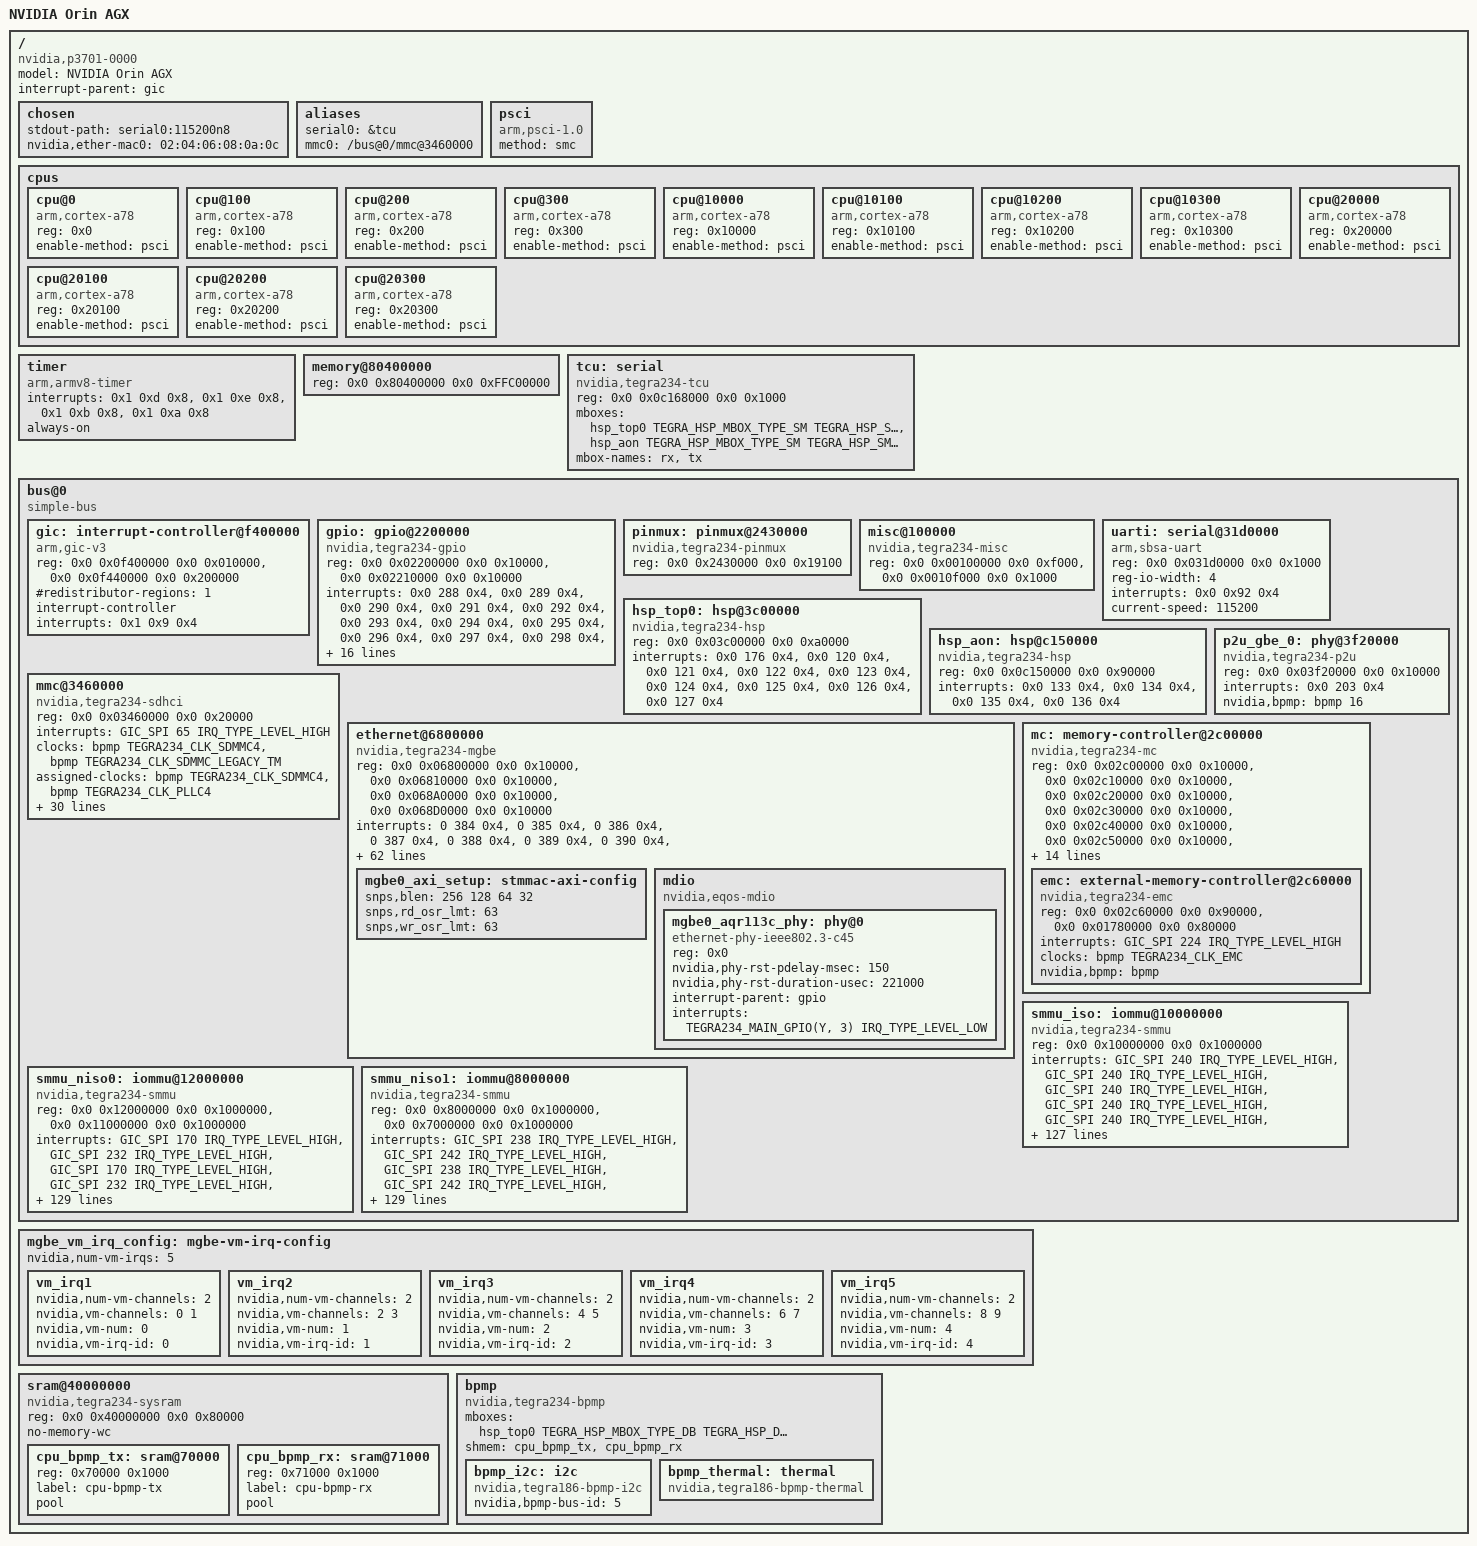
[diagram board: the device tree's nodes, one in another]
/*
 * Copyright 2024, Technology Innovation Institute
 *
 * SPDX-License-Identifier: GPL-2.0-only
 *
 * Device tree for NVIDIA Orin AGX (Tegra234)
 * Minimal DTS for seL4 kernel boot
 */

/dts-v1/;

/* dt-bindings headers for symbolic constants (requires cpp preprocessing) */
#include <dt-bindings/clock/tegra234-clock.h>
#include <dt-bindings/gpio/tegra234-gpio.h>
#include <dt-bindings/interrupt-controller/arm-gic.h>
#include <dt-bindings/mailbox/tegra186-hsp.h>
#include <dt-bindings/memory/tegra234-mc.h>
#include <dt-bindings/power/tegra234-powergate.h>
#include <dt-bindings/reset/tegra234-reset.h>

/ {
	model = "NVIDIA Orin AGX";
	compatible = "nvidia,p3701-0000", "nvidia,tegra234";
	interrupt-parent = <&gic>;
	#address-cells = <0x2>;
	#size-cells = <0x2>;

	chosen {
		stdout-path = "serial0:115200n8";
		/* MAC address for MGBE0 (nvidia,mac-addr-idx=0) */
		nvidia,ether-mac0 = "02:04:06:08:0a:0c";
	};

	aliases {
		serial0 = &tcu;
		mmc0 = "/bus@0/mmc@3460000";
	};

	psci {
		compatible = "arm,psci-1.0", "arm,psci-0.2";
		method = "smc";
	};

	cpus {
		#address-cells = <0x1>;
		#size-cells = <0x0>;

		cpu@0 {
			compatible = "arm,cortex-a78";
			reg = <0x0>;
			device_type = "cpu";
			enable-method = "psci";
		};

		cpu@100 {
			compatible = "arm,cortex-a78";
			reg = <0x100>;
			device_type = "cpu";
			enable-method = "psci";
		};

		cpu@200 {
			compatible = "arm,cortex-a78";
			reg = <0x200>;
			device_type = "cpu";
			enable-method = "psci";
		};

		cpu@300 {
			compatible = "arm,cortex-a78";
			reg = <0x300>;
			device_type = "cpu";
			enable-method = "psci";
		};

		cpu@10000 {
			compatible = "arm,cortex-a78";
			reg = <0x10000>;
			device_type = "cpu";
			enable-method = "psci";
		};

		cpu@10100 {
			compatible = "arm,cortex-a78";
			reg = <0x10100>;
			device_type = "cpu";
			enable-method = "psci";
		};

		cpu@10200 {
			compatible = "arm,cortex-a78";
			reg = <0x10200>;
			device_type = "cpu";
			enable-method = "psci";
		};

		cpu@10300 {
			compatible = "arm,cortex-a78";
			reg = <0x10300>;
			device_type = "cpu";
			enable-method = "psci";
		};

		cpu@20000 {
			compatible = "arm,cortex-a78";
			reg = <0x20000>;
			device_type = "cpu";
			enable-method = "psci";
		};

		cpu@20100 {
			compatible = "arm,cortex-a78";
			reg = <0x20100>;
			device_type = "cpu";
			enable-method = "psci";
		};

		cpu@20200 {
			compatible = "arm,cortex-a78";
			reg = <0x20200>;
			device_type = "cpu";
			enable-method = "psci";
		};

		cpu@20300 {
			compatible = "arm,cortex-a78";
			reg = <0x20300>;
			device_type = "cpu";
			enable-method = "psci";
		};
	};

	timer {
		compatible = "arm,armv8-timer";
		interrupts = <0x1 0xd 0x8>,  /* Secure Phys IRQ */
			     <0x1 0xe 0x8>,  /* Non-secure Phys IRQ */
			     <0x1 0xb 0x8>,  /* Virt IRQ */
			     <0x1 0xa 0x8>;  /* Hyp IRQ */
		always-on;
	};

	memory@80400000 {
		device_type = "memory";
		/* 4092MB RAM starting at 0x80400000 */
		reg = <0x0 0x80400000 0x0 0xFFC00000>;
	};

        tcu: serial {
                compatible = "nvidia,tegra234-tcu", "nvidia,tegra194-tcu";
                reg = <0x0 0x0c168000 0x0 0x1000>;
                mboxes = <&hsp_top0 TEGRA_HSP_MBOX_TYPE_SM TEGRA_HSP_SM_RX(0)>,
                         <&hsp_aon TEGRA_HSP_MBOX_TYPE_SM TEGRA_HSP_SM_TX(1)>;
                mbox-names = "rx", "tx";
                status = "okay";
        };

	/*
	 * bus@0 - simple-bus for memory-mapped peripherals
	 * Matches L4T DTB structure for consistent paths
	 */
	bus@0 {
		compatible = "simple-bus";
		#address-cells = <0x2>;
		#size-cells = <0x2>;
		ranges = <0x0 0x0 0x0 0x0 0x100 0x0>;  /* 1:1 mapping */

		gic: interrupt-controller@f400000 {
			compatible = "arm,gic-v3";
			reg = <0x0 0x0f400000 0x0 0x010000>,  /* GICD */
			      <0x0 0x0f440000 0x0 0x200000>;  /* GICR */
			#redistributor-regions = <1>;
			#interrupt-cells = <0x3>;
			interrupt-controller;
			interrupts = <0x1 0x9 0x4>;  /* GIC maintenance interrupt */
		};

		/*
		 * GPIO controller - Main GPIO
		 * Required for PHY reset on MGBE0 Ethernet
		 */
		gpio: gpio@2200000 {
			compatible = "nvidia,tegra234-gpio";
			reg-names = "security", "gpio";
			reg = <0x0 0x02200000 0x0 0x10000>,
			      <0x0 0x02210000 0x0 0x10000>;
			interrupts = <0x0 288 0x4>, <0x0 289 0x4>, <0x0 290 0x4>,
				     <0x0 291 0x4>, <0x0 292 0x4>, <0x0 293 0x4>,
				     <0x0 294 0x4>, <0x0 295 0x4>, <0x0 296 0x4>,
				     <0x0 297 0x4>, <0x0 298 0x4>, <0x0 299 0x4>,
				     <0x0 300 0x4>, <0x0 301 0x4>, <0x0 302 0x4>,
				     <0x0 303 0x4>, <0x0 304 0x4>, <0x0 305 0x4>,
				     <0x0 306 0x4>, <0x0 307 0x4>, <0x0 308 0x4>,
				     <0x0 309 0x4>, <0x0 310 0x4>, <0x0 311 0x4>,
				     <0x0 312 0x4>, <0x0 313 0x4>, <0x0 314 0x4>,
				     <0x0 315 0x4>, <0x0 316 0x4>, <0x0 317 0x4>,
				     <0x0 318 0x4>, <0x0 319 0x4>, <0x0 320 0x4>,
				     <0x0 321 0x4>, <0x0 322 0x4>, <0x0 323 0x4>,
				     <0x0 324 0x4>, <0x0 325 0x4>, <0x0 326 0x4>,
				     <0x0 327 0x4>, <0x0 328 0x4>, <0x0 329 0x4>,
				     <0x0 330 0x4>, <0x0 331 0x4>, <0x0 332 0x4>,
				     <0x0 333 0x4>, <0x0 334 0x4>, <0x0 335 0x4>;
			#interrupt-cells = <2>;
			interrupt-controller;
			#gpio-cells = <2>;
			gpio-controller;
			gpio-ranges = <&pinmux 0 0 164>;
			status = "okay";
		};

		/*
		 * Pinmux controller - required by GPIO for gpio-ranges
		 */
		pinmux: pinmux@2430000 {
			compatible = "nvidia,tegra234-pinmux";
			reg = <0x0 0x2430000 0x0 0x19100>;
			status = "okay";
		};

		/*
		 * APB MISC - Tegra APB miscellaneous registers
		 * Required for tegra_is_silicon() used by BPMP driver
		 */
		misc@100000 {
			compatible = "nvidia,tegra234-misc";
			reg = <0x0 0x00100000 0x0 0xf000>,    /* MISC base */
			      <0x0 0x0010f000 0x0 0x1000>;    /* STRAPPING_OPT_A */
			status = "okay";
		};

		/*
		 * UARTI - SBSA UART for VM console
		 * Physical address: 0x31d0000, Interrupt: SPI 146 (0x92)
		 */
		uarti: serial@31d0000 {
			compatible = "arm,sbsa-uart";
			reg = <0x0 0x031d0000 0x0 0x1000>;
			reg-io-width = <4>;           /* 32-bit MMIO access */
			interrupts = <0x0 0x92 0x4>;  /* SPI 146, level high */
			current-speed = <115200>;
			status = "okay";
		};

		/* HSP Top0 - Hardware Synchronization Primitives */
		hsp_top0: hsp@3c00000 {
			compatible = "nvidia,tegra234-hsp", "nvidia,tegra194-hsp";
			reg = <0x0 0x03c00000 0x0 0xa0000>;
			interrupts = <0x0 176 0x4>,   /* doorbell */
				     <0x0 120 0x4>,   /* shared0 */
				     <0x0 121 0x4>,   /* shared1 */
				     <0x0 122 0x4>,   /* shared2 */
				     <0x0 123 0x4>,   /* shared3 */
				     <0x0 124 0x4>,   /* shared4 */
				     <0x0 125 0x4>,   /* shared5 */
				     <0x0 126 0x4>,   /* shared6 */
				     <0x0 127 0x4>;   /* shared7 */
			interrupt-names = "doorbell", "shared0", "shared1", "shared2",
					  "shared3", "shared4", "shared5", "shared6",
					  "shared7";
			#mbox-cells = <2>;
			status = "okay";
		};

		/* HSP AON - for TCU communication */
		hsp_aon: hsp@c150000 {
			compatible = "nvidia,tegra234-hsp", "nvidia,tegra194-hsp";
			reg = <0x0 0x0c150000 0x0 0x90000>;
			interrupts = <0x0 133 0x4>,   /* shared1 */
				     <0x0 134 0x4>,   /* shared2 */
				     <0x0 135 0x4>,   /* shared3 */
				     <0x0 136 0x4>;   /* shared4 */
			interrupt-names = "shared1", "shared2", "shared3", "shared4";
			#mbox-cells = <2>;
			status = "okay";
		};

		mmc@3460000 {
			compatible = "nvidia,tegra234-sdhci", "nvidia,tegra186-sdhci";
			reg = <0x0 0x03460000 0x0 0x20000>;
			interrupts = <GIC_SPI 65 IRQ_TYPE_LEVEL_HIGH>;
			clocks = <&bpmp TEGRA234_CLK_SDMMC4>,
				 <&bpmp TEGRA234_CLK_SDMMC_LEGACY_TM>;
			clock-names = "sdhci", "tmclk";
			assigned-clocks = <&bpmp TEGRA234_CLK_SDMMC4>,
					  <&bpmp TEGRA234_CLK_PLLC4>;
			assigned-clock-parents = <&bpmp TEGRA234_CLK_PLLC4>;
			resets = <&bpmp TEGRA234_RESET_SDMMC4>;
			reset-names = "sdhci";
			interconnects = <&mc TEGRA234_MEMORY_CLIENT_SDMMCRAB &emc>,
					<&mc TEGRA234_MEMORY_CLIENT_SDMMCWAB &emc>;
			interconnect-names = "dma-mem", "write";
			iommus = <&smmu_niso1 TEGRA234_SID_SDMMC4>;
			nvidia,pad-autocal-pull-up-offset-hs400 = <0x00>;
			nvidia,pad-autocal-pull-down-offset-hs400 = <0x00>;
			nvidia,pad-autocal-pull-up-offset-1v8-timeout = <0x0a>;
			nvidia,pad-autocal-pull-down-offset-1v8-timeout = <0x0a>;
			nvidia,pad-autocal-pull-up-offset-3v3-timeout = <0x0a>;
			nvidia,pad-autocal-pull-down-offset-3v3-timeout = <0x0a>;
			nvidia,default-tap = <0x8>;
			nvidia,default-trim = <0x14>;
			nvidia,dqs-trim = <40>;
			supports-cqe;
			status = "okay";
                        mmc-ddr-1_8v;
                        mmc-hs200-1_8v;
                        mmc-hs400-1_8v;
                        mmc-hs400-enhanced-strobe;
                        cap-sd-highspeed;
                        cap-mmc-highspeed;
			bus-width = <8>;
			non-removable;

		};

		/*
		 * P2U PHY for MGBE0 - Tegra SerDes PHY
		 * Physical address: 0x3f20000, Interrupt: SPI 203
		 */
		p2u_gbe_0: phy@3f20000 {
			compatible = "nvidia,tegra234-p2u";
			reg = <0x0 0x03f20000 0x0 0x10000>;
			reg-names = "ctl";
			interrupts = <0x0 203 0x4>;   /* SPI 203, level high */
			interrupt-names = "intr";
			nvidia,bpmp = <&bpmp 16>;
			#phy-cells = <0>;
			status = "okay";
		};


		/*
		 * MGBE0 - Multi-Gigabit Ethernet controller
		 * Verbatim from tegra234-base-overlay.dtsi + tegra234-p3737-0000+p3701-0000.dts
		 */
		ethernet@6800000 {
			compatible = "nvidia,tegra234-mgbe";
			reg = <0x0 0x06800000 0x0 0x10000>, /* HV base */
			      <0x0 0x06810000 0x0 0x10000>, /* MGBE base */
			      <0x0 0x068A0000 0x0 0x10000>, /* XPCS base */
			      <0x0 0x068D0000 0x0 0x10000>; /* MACsec RM base */
			reg-names = "hypervisor", "mac", "xpcs", "macsec-base";
			interrupts = <0 384 0x4>,    /* common */
				     <0 385 0x4>,    /* vm0 */
				     <0 386 0x4>,    /* vm1 */
				     <0 387 0x4>,    /* vm2 */
				     <0 388 0x4>,    /* vm3 */
				     <0 389 0x4>,    /* vm4 */
				     <0 390 0x4>,    /* MACsec non-secure intr */
				     <0 391 0x4>;    /* MACsec secure intr */
			interrupt-names = "common", "vm0", "vm1", "vm2", "vm3", "vm4",
					  "macsec-ns-irq", "macsec-s-irq";
			clocks = <&bpmp TEGRA234_CLK_MGBE0_RX_INPUT_M>,
				 <&bpmp TEGRA234_CLK_MGBE0_RX_PCS_M>,
				 <&bpmp TEGRA234_CLK_MGBE0_RX_PCS_INPUT>,
				 <&bpmp TEGRA234_CLK_MGBE0_RX_PCS>,
				 <&bpmp TEGRA234_CLK_MGBE0_TX>,
				 <&bpmp TEGRA234_CLK_MGBE0_TX_PCS>,
				 <&bpmp TEGRA234_CLK_MGBE0_MAC_DIVIDER>,
				 <&bpmp TEGRA234_CLK_MGBE0_MAC>,
				 <&bpmp TEGRA234_CLK_MGBE0_EEE_PCS>,
				 <&bpmp TEGRA234_CLK_MGBE0_APP>,
				 <&bpmp TEGRA234_CLK_MGBE0_PTP_REF>,
				 <&bpmp TEGRA234_CLK_MGBE0_MACSEC>,
				 <&bpmp TEGRA234_CLK_MGBE0_RX_INPUT>;
			clock-names = "rx-input-m", "rx-pcs-m", "rx-pcs-input",
				      "rx-pcs", "tx", "tx-pcs", "mac-divider",
				      "mac", "eee-pcs", "mgbe", "ptp-ref",
				      "mgbe_macsec", "rx-input";
			resets = <&bpmp TEGRA234_RESET_MGBE0_MAC>,
				 <&bpmp TEGRA234_RESET_MGBE0_PCS>,
				 <&bpmp TEGRA234_RESET_MGBE0_MACSEC>; /* MACsec non-secure reset */
			reset-names = "mac", "pcs", "macsec_ns_rst";
			/* SMMU reference - MGBE StreamID is 0x06
			 * MGBE requires active SMMU (bypass mode doesn't work)
			 * NOTE: MGBE uses smmu_niso0, not smmu_niso1! */
			iommus = <&smmu_niso0 0x06>;
			interconnects = <&mc TEGRA234_MEMORY_CLIENT_MGBEARD &emc>,
					<&mc TEGRA234_MEMORY_CLIENT_MGBEAWR &emc>;
			interconnect-names = "dma-mem", "write";
			power-domains = <&bpmp TEGRA234_POWER_DOMAIN_MGBEB>;
			nvidia,vm-irq-config = <&mgbe_vm_irq_config>;
			nvidia,num-dma-chans = <10>;
			nvidia,dma-chans = <0 1 2 3 4 5 6 7 8 9>;
			nvidia,num-mtl-queues = <10>;
			nvidia,mtl-queues = <0 1 2 3 4 5 6 7 8 9>;
			nvidia,tc-mapping = <0 1 2 3 4 5 6 7 0 1>;
			/* Residual Queue can be any valid queue except RxQ0 */
			nvidia,residual-queue = <1>;
			nvidia,rxq_enable_ctrl = <2 2 2 2 2 2 2 2 2 2>;
			nvidia,tx-queue-prio = <0 1 2 3 4 5 6 7 0 0>;
			nvidia,rx-queue-prio = <0x1 0x2 0x4 0x8 0x10 0x20 0x40 0x80 0x0 0x0>;
			nvidia,dcs-enable = <0x1>;
			nvidia,macsec-enable = <0>;
			nvidia,rx_riwt = <512>;
			nvidia,rx_frames = <64>;
			nvidia,tx_usecs = <256>;
			nvidia,tx_frames = <16>;
			nvidia,promisc_mode = <1>;
			nvidia,slot_num_check = <0x0 0x0 0x0 0x0 0x0 0x0 0x0 0x0 0x0 0x0>;
			nvidia,slot_intvl_vals = <0x0 0x7D 0x7D 0x7D 0x7D 0x7D 0x7D 0x7D 0x7D 0x7D>;
			nvidia,ptp_ref_clock_speed = <312500000>;
			nvidia,instance_id = <0>; /* MGBE0 instance */
			nvidia,ptp-rx-queue = <3>;
			nvidia,dma_rx_ring_sz = <4096>;
			nvidia,dma_tx_ring_sz = <4096>;
			dma-coherent;
			status = "okay";

			/* From tegra234-p3737-0000.dtsi - board specific */
			nvidia,mac-addr-idx = <0>;
			/* MAC address for VM - driver falls back to of_get_mac_address() */
			local-mac-address = [02 04 06 08 0a 0c];
			nvidia,max-platform-mtu = <16383>;
			/* 1=enable, 0=disable */
			nvidia,pause_frames = <1>;
			/* 0:XFI 10G, 1:XFI 5G, 2:USXGMII 10G, 3:USXGMII 5G */
			nvidia,phy-iface-mode = <0>;
			nvidia,phy-reset-gpio = <&gpio TEGRA234_MAIN_GPIO(Y, 1) 0>;
			nvidia,mdio_addr = <0>;

			/* From tegra234-p3737-0000+p3701-0000.dts */
			phy-handle = <&mgbe0_aqr113c_phy>;
			phy-mode = "10gbase-r";

			snps,axi-config = <&mgbe0_axi_setup>;

			mgbe0_axi_setup: stmmac-axi-config {
				snps,blen = <256 128 64 32>;
				snps,rd_osr_lmt = <63>;
				snps,wr_osr_lmt = <63>;
			};

			/* From tegra234-p3737-0000.dtsi - NVIDIA MDIO */
			mdio {
				compatible = "nvidia,eqos-mdio";
				#address-cells = <1>;
				#size-cells = <0>;

				mgbe0_aqr113c_phy: phy@0 {
					compatible = "ethernet-phy-ieee802.3-c45";
					reg = <0x0>;
					#phy-cells = <0>;
					nvidia,phy-rst-pdelay-msec = <150>; /* msec */
					nvidia,phy-rst-duration-usec = <221000>; /* usec */
					interrupt-parent = <&gpio>;
					interrupts = <TEGRA234_MAIN_GPIO(Y, 3) IRQ_TYPE_LEVEL_LOW>;
				};
			};
		};

		/*
		 * Memory Controller - needed for SMMU SID programming */

		mc: memory-controller@2c00000 {
			compatible = "nvidia,tegra234-mc";
			reg = <0x0 0x02c00000 0x0 0x10000>,   /* MC-SID */
			      <0x0 0x02c10000 0x0 0x10000>,   /* MC Broadcast*/
			      <0x0 0x02c20000 0x0 0x10000>,   /* MC0 */
			      <0x0 0x02c30000 0x0 0x10000>,   /* MC1 */
			      <0x0 0x02c40000 0x0 0x10000>,   /* MC2 */
			      <0x0 0x02c50000 0x0 0x10000>,   /* MC3 */
			      <0x0 0x02b80000 0x0 0x10000>,   /* MC4 */
			      <0x0 0x02b90000 0x0 0x10000>,   /* MC5 */
			      <0x0 0x02ba0000 0x0 0x10000>,   /* MC6 */
			      <0x0 0x02bb0000 0x0 0x10000>,   /* MC7 */
			      <0x0 0x01700000 0x0 0x10000>,   /* MC8 */
			      <0x0 0x01710000 0x0 0x10000>,   /* MC9 */
			      <0x0 0x01720000 0x0 0x10000>,   /* MC10 */
			      <0x0 0x01730000 0x0 0x10000>,   /* MC11 */
			      <0x0 0x01740000 0x0 0x10000>,   /* MC12 */
			      <0x0 0x01750000 0x0 0x10000>,   /* MC13 */
			      <0x0 0x01760000 0x0 0x10000>,   /* MC14 */
			      <0x0 0x01770000 0x0 0x10000>;   /* MC15 */
			reg-names = "sid", "broadcast", "ch0", "ch1", "ch2", "ch3",
				    "ch4", "ch5", "ch6", "ch7", "ch8", "ch9", "ch10",
				    "ch11", "ch12", "ch13", "ch14", "ch15";
			interrupts = <GIC_SPI 223 IRQ_TYPE_LEVEL_HIGH>;
			#interconnect-cells = <1>;
			status = "okay";

			#address-cells = <2>;
			#size-cells = <2>;
			ranges = <0x0 0x01700000 0x0 0x01700000 0x0 0x100000>,
				 <0x0 0x02b80000 0x0 0x02b80000 0x0 0x040000>,
				 <0x0 0x02c00000 0x0 0x02c00000 0x0 0x100000>;

			/*
			 * Bit 39 of addresses passing through the memory
			 * controller selects the XBAR format used when memory
			 * is accessed. This is used to transparently access
			 * memory in the XBAR format used by the discrete GPU
			 * (bit 39 set) or Tegra (bit 39 clear).
			 *
			 * As a consequence, the operating system must ensure
			 * that bit 39 is never used implicitly, for example
			 * via an I/O virtual address mapping of an IOMMU. If
			 * devices require access to the XBAR switch, their
			 * drivers must set this bit explicitly.
			 *
			 * Limit the DMA range for memory clients to [38:0].
			 */
			dma-ranges = <0x0 0x0 0x0 0x0 0x80 0x0>;

			emc: external-memory-controller@2c60000 {
				compatible = "nvidia,tegra234-emc";
				reg = <0x0 0x02c60000 0x0 0x90000>,
				      <0x0 0x01780000 0x0 0x80000>;
				interrupts = <GIC_SPI 224 IRQ_TYPE_LEVEL_HIGH>;
				clocks = <&bpmp TEGRA234_CLK_EMC>;
				clock-names = "emc";
				status = "okay";

				#interconnect-cells = <0>;

				nvidia,bpmp = <&bpmp>;
			};
		};


		/*
		 * SMMU instances - passed through to VM for MGBE DMA
		 * MGBE requires active SMMU translation (bypass mode doesn't work)
		 */
		 smmu_iso: iommu@10000000 {
			compatible = "nvidia,tegra234-smmu", "nvidia,smmu-500";
			reg = <0x0 0x10000000 0x0 0x1000000>;
			interrupts = <GIC_SPI 240 IRQ_TYPE_LEVEL_HIGH>,
				     <GIC_SPI 240 IRQ_TYPE_LEVEL_HIGH>,
				     <GIC_SPI 240 IRQ_TYPE_LEVEL_HIGH>,
				     <GIC_SPI 240 IRQ_TYPE_LEVEL_HIGH>,
				     <GIC_SPI 240 IRQ_TYPE_LEVEL_HIGH>,
				     <GIC_SPI 240 IRQ_TYPE_LEVEL_HIGH>,
				     <GIC_SPI 240 IRQ_TYPE_LEVEL_HIGH>,
				     <GIC_SPI 240 IRQ_TYPE_LEVEL_HIGH>,
				     <GIC_SPI 240 IRQ_TYPE_LEVEL_HIGH>,
				     <GIC_SPI 240 IRQ_TYPE_LEVEL_HIGH>,
				     <GIC_SPI 240 IRQ_TYPE_LEVEL_HIGH>,
				     <GIC_SPI 240 IRQ_TYPE_LEVEL_HIGH>,
				     <GIC_SPI 240 IRQ_TYPE_LEVEL_HIGH>,
				     <GIC_SPI 240 IRQ_TYPE_LEVEL_HIGH>,
				     <GIC_SPI 240 IRQ_TYPE_LEVEL_HIGH>,
				     <GIC_SPI 240 IRQ_TYPE_LEVEL_HIGH>,
				     <GIC_SPI 240 IRQ_TYPE_LEVEL_HIGH>,
				     <GIC_SPI 240 IRQ_TYPE_LEVEL_HIGH>,
				     <GIC_SPI 240 IRQ_TYPE_LEVEL_HIGH>,
				     <GIC_SPI 240 IRQ_TYPE_LEVEL_HIGH>,
				     <GIC_SPI 240 IRQ_TYPE_LEVEL_HIGH>,
				     <GIC_SPI 240 IRQ_TYPE_LEVEL_HIGH>,
				     <GIC_SPI 240 IRQ_TYPE_LEVEL_HIGH>,
				     <GIC_SPI 240 IRQ_TYPE_LEVEL_HIGH>,
				     <GIC_SPI 240 IRQ_TYPE_LEVEL_HIGH>,
				     <GIC_SPI 240 IRQ_TYPE_LEVEL_HIGH>,
				     <GIC_SPI 240 IRQ_TYPE_LEVEL_HIGH>,
				     <GIC_SPI 240 IRQ_TYPE_LEVEL_HIGH>,
				     <GIC_SPI 240 IRQ_TYPE_LEVEL_HIGH>,
				     <GIC_SPI 240 IRQ_TYPE_LEVEL_HIGH>,
				     <GIC_SPI 240 IRQ_TYPE_LEVEL_HIGH>,
				     <GIC_SPI 240 IRQ_TYPE_LEVEL_HIGH>,
				     <GIC_SPI 240 IRQ_TYPE_LEVEL_HIGH>,
				     <GIC_SPI 240 IRQ_TYPE_LEVEL_HIGH>,
				     <GIC_SPI 240 IRQ_TYPE_LEVEL_HIGH>,
				     <GIC_SPI 240 IRQ_TYPE_LEVEL_HIGH>,
				     <GIC_SPI 240 IRQ_TYPE_LEVEL_HIGH>,
				     <GIC_SPI 240 IRQ_TYPE_LEVEL_HIGH>,
				     <GIC_SPI 240 IRQ_TYPE_LEVEL_HIGH>,
				     <GIC_SPI 240 IRQ_TYPE_LEVEL_HIGH>,
				     <GIC_SPI 240 IRQ_TYPE_LEVEL_HIGH>,
				     <GIC_SPI 240 IRQ_TYPE_LEVEL_HIGH>,
				     <GIC_SPI 240 IRQ_TYPE_LEVEL_HIGH>,
				     <GIC_SPI 240 IRQ_TYPE_LEVEL_HIGH>,
				     <GIC_SPI 240 IRQ_TYPE_LEVEL_HIGH>,
				     <GIC_SPI 240 IRQ_TYPE_LEVEL_HIGH>,
				     <GIC_SPI 240 IRQ_TYPE_LEVEL_HIGH>,
				     <GIC_SPI 240 IRQ_TYPE_LEVEL_HIGH>,
				     <GIC_SPI 240 IRQ_TYPE_LEVEL_HIGH>,
				     <GIC_SPI 240 IRQ_TYPE_LEVEL_HIGH>,
				     <GIC_SPI 240 IRQ_TYPE_LEVEL_HIGH>,
				     <GIC_SPI 240 IRQ_TYPE_LEVEL_HIGH>,
				     <GIC_SPI 240 IRQ_TYPE_LEVEL_HIGH>,
				     <GIC_SPI 240 IRQ_TYPE_LEVEL_HIGH>,
				     <GIC_SPI 240 IRQ_TYPE_LEVEL_HIGH>,
				     <GIC_SPI 240 IRQ_TYPE_LEVEL_HIGH>,
				     <GIC_SPI 240 IRQ_TYPE_LEVEL_HIGH>,
				     <GIC_SPI 240 IRQ_TYPE_LEVEL_HIGH>,
				     <GIC_SPI 240 IRQ_TYPE_LEVEL_HIGH>,
				     <GIC_SPI 240 IRQ_TYPE_LEVEL_HIGH>,
				     <GIC_SPI 240 IRQ_TYPE_LEVEL_HIGH>,
				     <GIC_SPI 240 IRQ_TYPE_LEVEL_HIGH>,
				     <GIC_SPI 240 IRQ_TYPE_LEVEL_HIGH>,
				     <GIC_SPI 240 IRQ_TYPE_LEVEL_HIGH>,
				     <GIC_SPI 240 IRQ_TYPE_LEVEL_HIGH>,
				     <GIC_SPI 240 IRQ_TYPE_LEVEL_HIGH>,
				     <GIC_SPI 240 IRQ_TYPE_LEVEL_HIGH>,
				     <GIC_SPI 240 IRQ_TYPE_LEVEL_HIGH>,
				     <GIC_SPI 240 IRQ_TYPE_LEVEL_HIGH>,
				     <GIC_SPI 240 IRQ_TYPE_LEVEL_HIGH>,
				     <GIC_SPI 240 IRQ_TYPE_LEVEL_HIGH>,
				     <GIC_SPI 240 IRQ_TYPE_LEVEL_HIGH>,
				     <GIC_SPI 240 IRQ_TYPE_LEVEL_HIGH>,
				     <GIC_SPI 240 IRQ_TYPE_LEVEL_HIGH>,
				     <GIC_SPI 240 IRQ_TYPE_LEVEL_HIGH>,
				     <GIC_SPI 240 IRQ_TYPE_LEVEL_HIGH>,
				     <GIC_SPI 240 IRQ_TYPE_LEVEL_HIGH>,
				     <GIC_SPI 240 IRQ_TYPE_LEVEL_HIGH>,
				     <GIC_SPI 240 IRQ_TYPE_LEVEL_HIGH>,
				     <GIC_SPI 240 IRQ_TYPE_LEVEL_HIGH>,
				     <GIC_SPI 240 IRQ_TYPE_LEVEL_HIGH>,
				     <GIC_SPI 240 IRQ_TYPE_LEVEL_HIGH>,
				     <GIC_SPI 240 IRQ_TYPE_LEVEL_HIGH>,
				     <GIC_SPI 240 IRQ_TYPE_LEVEL_HIGH>,
				     <GIC_SPI 240 IRQ_TYPE_LEVEL_HIGH>,
				     <GIC_SPI 240 IRQ_TYPE_LEVEL_HIGH>,
				     <GIC_SPI 240 IRQ_TYPE_LEVEL_HIGH>,
				     <GIC_SPI 240 IRQ_TYPE_LEVEL_HIGH>,
				     <GIC_SPI 240 IRQ_TYPE_LEVEL_HIGH>,
				     <GIC_SPI 240 IRQ_TYPE_LEVEL_HIGH>,
				     <GIC_SPI 240 IRQ_TYPE_LEVEL_HIGH>,
				     <GIC_SPI 240 IRQ_TYPE_LEVEL_HIGH>,
				     <GIC_SPI 240 IRQ_TYPE_LEVEL_HIGH>,
				     <GIC_SPI 240 IRQ_TYPE_LEVEL_HIGH>,
				     <GIC_SPI 240 IRQ_TYPE_LEVEL_HIGH>,
				     <GIC_SPI 240 IRQ_TYPE_LEVEL_HIGH>,
				     <GIC_SPI 240 IRQ_TYPE_LEVEL_HIGH>,
				     <GIC_SPI 240 IRQ_TYPE_LEVEL_HIGH>,
				     <GIC_SPI 240 IRQ_TYPE_LEVEL_HIGH>,
				     <GIC_SPI 240 IRQ_TYPE_LEVEL_HIGH>,
				     <GIC_SPI 240 IRQ_TYPE_LEVEL_HIGH>,
				     <GIC_SPI 240 IRQ_TYPE_LEVEL_HIGH>,
				     <GIC_SPI 240 IRQ_TYPE_LEVEL_HIGH>,
				     <GIC_SPI 240 IRQ_TYPE_LEVEL_HIGH>,
				     <GIC_SPI 240 IRQ_TYPE_LEVEL_HIGH>,
				     <GIC_SPI 240 IRQ_TYPE_LEVEL_HIGH>,
				     <GIC_SPI 240 IRQ_TYPE_LEVEL_HIGH>,
				     <GIC_SPI 240 IRQ_TYPE_LEVEL_HIGH>,
				     <GIC_SPI 240 IRQ_TYPE_LEVEL_HIGH>,
				     <GIC_SPI 240 IRQ_TYPE_LEVEL_HIGH>,
				     <GIC_SPI 240 IRQ_TYPE_LEVEL_HIGH>,
				     <GIC_SPI 240 IRQ_TYPE_LEVEL_HIGH>,
				     <GIC_SPI 240 IRQ_TYPE_LEVEL_HIGH>,
				     <GIC_SPI 240 IRQ_TYPE_LEVEL_HIGH>,
				     <GIC_SPI 240 IRQ_TYPE_LEVEL_HIGH>,
				     <GIC_SPI 240 IRQ_TYPE_LEVEL_HIGH>,
				     <GIC_SPI 240 IRQ_TYPE_LEVEL_HIGH>,
				     <GIC_SPI 240 IRQ_TYPE_LEVEL_HIGH>,
				     <GIC_SPI 240 IRQ_TYPE_LEVEL_HIGH>,
				     <GIC_SPI 240 IRQ_TYPE_LEVEL_HIGH>,
				     <GIC_SPI 240 IRQ_TYPE_LEVEL_HIGH>,
				     <GIC_SPI 240 IRQ_TYPE_LEVEL_HIGH>,
				     <GIC_SPI 240 IRQ_TYPE_LEVEL_HIGH>,
				     <GIC_SPI 240 IRQ_TYPE_LEVEL_HIGH>,
				     <GIC_SPI 240 IRQ_TYPE_LEVEL_HIGH>,
				     <GIC_SPI 240 IRQ_TYPE_LEVEL_HIGH>,
				     <GIC_SPI 240 IRQ_TYPE_LEVEL_HIGH>,
				     <GIC_SPI 240 IRQ_TYPE_LEVEL_HIGH>,
				     <GIC_SPI 240 IRQ_TYPE_LEVEL_HIGH>;
			stream-match-mask = <0x7f80>;
			#global-interrupts = <1>;
			#iommu-cells = <1>;

			nvidia,memory-controller = <&mc>;
			status = "okay";
		};

		smmu_niso0: iommu@12000000 {
			compatible = "nvidia,tegra234-smmu", "nvidia,smmu-500";
			reg = <0x0 0x12000000 0x0 0x1000000>,
			      <0x0 0x11000000 0x0 0x1000000>;
			interrupts = <GIC_SPI 170 IRQ_TYPE_LEVEL_HIGH>,
				     <GIC_SPI 232 IRQ_TYPE_LEVEL_HIGH>,
				     <GIC_SPI 170 IRQ_TYPE_LEVEL_HIGH>,
				     <GIC_SPI 232 IRQ_TYPE_LEVEL_HIGH>,
				     <GIC_SPI 170 IRQ_TYPE_LEVEL_HIGH>,
				     <GIC_SPI 170 IRQ_TYPE_LEVEL_HIGH>,
				     <GIC_SPI 170 IRQ_TYPE_LEVEL_HIGH>,
				     <GIC_SPI 170 IRQ_TYPE_LEVEL_HIGH>,
				     <GIC_SPI 170 IRQ_TYPE_LEVEL_HIGH>,
				     <GIC_SPI 170 IRQ_TYPE_LEVEL_HIGH>,
				     <GIC_SPI 170 IRQ_TYPE_LEVEL_HIGH>,
				     <GIC_SPI 170 IRQ_TYPE_LEVEL_HIGH>,
				     <GIC_SPI 170 IRQ_TYPE_LEVEL_HIGH>,
				     <GIC_SPI 170 IRQ_TYPE_LEVEL_HIGH>,
				     <GIC_SPI 170 IRQ_TYPE_LEVEL_HIGH>,
				     <GIC_SPI 170 IRQ_TYPE_LEVEL_HIGH>,
				     <GIC_SPI 170 IRQ_TYPE_LEVEL_HIGH>,
				     <GIC_SPI 170 IRQ_TYPE_LEVEL_HIGH>,
				     <GIC_SPI 170 IRQ_TYPE_LEVEL_HIGH>,
				     <GIC_SPI 170 IRQ_TYPE_LEVEL_HIGH>,
				     <GIC_SPI 170 IRQ_TYPE_LEVEL_HIGH>,
				     <GIC_SPI 170 IRQ_TYPE_LEVEL_HIGH>,
				     <GIC_SPI 170 IRQ_TYPE_LEVEL_HIGH>,
				     <GIC_SPI 170 IRQ_TYPE_LEVEL_HIGH>,
				     <GIC_SPI 170 IRQ_TYPE_LEVEL_HIGH>,
				     <GIC_SPI 170 IRQ_TYPE_LEVEL_HIGH>,
				     <GIC_SPI 170 IRQ_TYPE_LEVEL_HIGH>,
				     <GIC_SPI 170 IRQ_TYPE_LEVEL_HIGH>,
				     <GIC_SPI 170 IRQ_TYPE_LEVEL_HIGH>,
				     <GIC_SPI 170 IRQ_TYPE_LEVEL_HIGH>,
				     <GIC_SPI 170 IRQ_TYPE_LEVEL_HIGH>,
				     <GIC_SPI 170 IRQ_TYPE_LEVEL_HIGH>,
				     <GIC_SPI 170 IRQ_TYPE_LEVEL_HIGH>,
				     <GIC_SPI 170 IRQ_TYPE_LEVEL_HIGH>,
				     <GIC_SPI 170 IRQ_TYPE_LEVEL_HIGH>,
				     <GIC_SPI 170 IRQ_TYPE_LEVEL_HIGH>,
				     <GIC_SPI 170 IRQ_TYPE_LEVEL_HIGH>,
				     <GIC_SPI 170 IRQ_TYPE_LEVEL_HIGH>,
				     <GIC_SPI 170 IRQ_TYPE_LEVEL_HIGH>,
				     <GIC_SPI 170 IRQ_TYPE_LEVEL_HIGH>,
				     <GIC_SPI 170 IRQ_TYPE_LEVEL_HIGH>,
				     <GIC_SPI 170 IRQ_TYPE_LEVEL_HIGH>,
				     <GIC_SPI 170 IRQ_TYPE_LEVEL_HIGH>,
				     <GIC_SPI 170 IRQ_TYPE_LEVEL_HIGH>,
				     <GIC_SPI 170 IRQ_TYPE_LEVEL_HIGH>,
				     <GIC_SPI 170 IRQ_TYPE_LEVEL_HIGH>,
				     <GIC_SPI 170 IRQ_TYPE_LEVEL_HIGH>,
				     <GIC_SPI 170 IRQ_TYPE_LEVEL_HIGH>,
				     <GIC_SPI 170 IRQ_TYPE_LEVEL_HIGH>,
				     <GIC_SPI 170 IRQ_TYPE_LEVEL_HIGH>,
				     <GIC_SPI 170 IRQ_TYPE_LEVEL_HIGH>,
				     <GIC_SPI 170 IRQ_TYPE_LEVEL_HIGH>,
				     <GIC_SPI 170 IRQ_TYPE_LEVEL_HIGH>,
				     <GIC_SPI 170 IRQ_TYPE_LEVEL_HIGH>,
				     <GIC_SPI 170 IRQ_TYPE_LEVEL_HIGH>,
				     <GIC_SPI 170 IRQ_TYPE_LEVEL_HIGH>,
				     <GIC_SPI 170 IRQ_TYPE_LEVEL_HIGH>,
				     <GIC_SPI 170 IRQ_TYPE_LEVEL_HIGH>,
				     <GIC_SPI 170 IRQ_TYPE_LEVEL_HIGH>,
				     <GIC_SPI 170 IRQ_TYPE_LEVEL_HIGH>,
				     <GIC_SPI 170 IRQ_TYPE_LEVEL_HIGH>,
				     <GIC_SPI 170 IRQ_TYPE_LEVEL_HIGH>,
				     <GIC_SPI 170 IRQ_TYPE_LEVEL_HIGH>,
				     <GIC_SPI 170 IRQ_TYPE_LEVEL_HIGH>,
				     <GIC_SPI 170 IRQ_TYPE_LEVEL_HIGH>,
				     <GIC_SPI 170 IRQ_TYPE_LEVEL_HIGH>,
				     <GIC_SPI 170 IRQ_TYPE_LEVEL_HIGH>,
				     <GIC_SPI 170 IRQ_TYPE_LEVEL_HIGH>,
				     <GIC_SPI 170 IRQ_TYPE_LEVEL_HIGH>,
				     <GIC_SPI 170 IRQ_TYPE_LEVEL_HIGH>,
				     <GIC_SPI 170 IRQ_TYPE_LEVEL_HIGH>,
				     <GIC_SPI 170 IRQ_TYPE_LEVEL_HIGH>,
				     <GIC_SPI 170 IRQ_TYPE_LEVEL_HIGH>,
				     <GIC_SPI 170 IRQ_TYPE_LEVEL_HIGH>,
				     <GIC_SPI 170 IRQ_TYPE_LEVEL_HIGH>,
				     <GIC_SPI 170 IRQ_TYPE_LEVEL_HIGH>,
				     <GIC_SPI 170 IRQ_TYPE_LEVEL_HIGH>,
				     <GIC_SPI 170 IRQ_TYPE_LEVEL_HIGH>,
				     <GIC_SPI 170 IRQ_TYPE_LEVEL_HIGH>,
				     <GIC_SPI 170 IRQ_TYPE_LEVEL_HIGH>,
				     <GIC_SPI 170 IRQ_TYPE_LEVEL_HIGH>,
				     <GIC_SPI 170 IRQ_TYPE_LEVEL_HIGH>,
				     <GIC_SPI 170 IRQ_TYPE_LEVEL_HIGH>,
				     <GIC_SPI 170 IRQ_TYPE_LEVEL_HIGH>,
				     <GIC_SPI 170 IRQ_TYPE_LEVEL_HIGH>,
				     <GIC_SPI 170 IRQ_TYPE_LEVEL_HIGH>,
				     <GIC_SPI 170 IRQ_TYPE_LEVEL_HIGH>,
				     <GIC_SPI 170 IRQ_TYPE_LEVEL_HIGH>,
				     <GIC_SPI 170 IRQ_TYPE_LEVEL_HIGH>,
				     <GIC_SPI 170 IRQ_TYPE_LEVEL_HIGH>,
				     <GIC_SPI 170 IRQ_TYPE_LEVEL_HIGH>,
				     <GIC_SPI 170 IRQ_TYPE_LEVEL_HIGH>,
				     <GIC_SPI 170 IRQ_TYPE_LEVEL_HIGH>,
				     <GIC_SPI 170 IRQ_TYPE_LEVEL_HIGH>,
				     <GIC_SPI 170 IRQ_TYPE_LEVEL_HIGH>,
				     <GIC_SPI 170 IRQ_TYPE_LEVEL_HIGH>,
				     <GIC_SPI 170 IRQ_TYPE_LEVEL_HIGH>,
				     <GIC_SPI 170 IRQ_TYPE_LEVEL_HIGH>,
				     <GIC_SPI 170 IRQ_TYPE_LEVEL_HIGH>,
				     <GIC_SPI 170 IRQ_TYPE_LEVEL_HIGH>,
				     <GIC_SPI 170 IRQ_TYPE_LEVEL_HIGH>,
				     <GIC_SPI 170 IRQ_TYPE_LEVEL_HIGH>,
				     <GIC_SPI 170 IRQ_TYPE_LEVEL_HIGH>,
				     <GIC_SPI 170 IRQ_TYPE_LEVEL_HIGH>,
				     <GIC_SPI 170 IRQ_TYPE_LEVEL_HIGH>,
				     <GIC_SPI 170 IRQ_TYPE_LEVEL_HIGH>,
				     <GIC_SPI 170 IRQ_TYPE_LEVEL_HIGH>,
				     <GIC_SPI 170 IRQ_TYPE_LEVEL_HIGH>,
				     <GIC_SPI 170 IRQ_TYPE_LEVEL_HIGH>,
				     <GIC_SPI 170 IRQ_TYPE_LEVEL_HIGH>,
				     <GIC_SPI 170 IRQ_TYPE_LEVEL_HIGH>,
				     <GIC_SPI 170 IRQ_TYPE_LEVEL_HIGH>,
				     <GIC_SPI 170 IRQ_TYPE_LEVEL_HIGH>,
				     <GIC_SPI 170 IRQ_TYPE_LEVEL_HIGH>,
				     <GIC_SPI 170 IRQ_TYPE_LEVEL_HIGH>,
				     <GIC_SPI 170 IRQ_TYPE_LEVEL_HIGH>,
				     <GIC_SPI 170 IRQ_TYPE_LEVEL_HIGH>,
				     <GIC_SPI 170 IRQ_TYPE_LEVEL_HIGH>,
				     <GIC_SPI 170 IRQ_TYPE_LEVEL_HIGH>,
				     <GIC_SPI 170 IRQ_TYPE_LEVEL_HIGH>,
				     <GIC_SPI 170 IRQ_TYPE_LEVEL_HIGH>,
				     <GIC_SPI 170 IRQ_TYPE_LEVEL_HIGH>,
				     <GIC_SPI 170 IRQ_TYPE_LEVEL_HIGH>,
				     <GIC_SPI 170 IRQ_TYPE_LEVEL_HIGH>,
				     <GIC_SPI 170 IRQ_TYPE_LEVEL_HIGH>,
				     <GIC_SPI 170 IRQ_TYPE_LEVEL_HIGH>,
				     <GIC_SPI 170 IRQ_TYPE_LEVEL_HIGH>,
				     <GIC_SPI 170 IRQ_TYPE_LEVEL_HIGH>,
				     <GIC_SPI 170 IRQ_TYPE_LEVEL_HIGH>,
				     <GIC_SPI 170 IRQ_TYPE_LEVEL_HIGH>;
			stream-match-mask = <0x7f80>;
			#global-interrupts = <2>;
			#iommu-cells = <1>;

			nvidia,memory-controller = <&mc>;
			status = "okay";
		};

		smmu_niso1: iommu@8000000 {
			compatible = "nvidia,tegra234-smmu", "nvidia,smmu-500";
			reg = <0x0 0x8000000 0x0 0x1000000>,
			      <0x0 0x7000000 0x0 0x1000000>;
			interrupts = <GIC_SPI 238 IRQ_TYPE_LEVEL_HIGH>,
				     <GIC_SPI 242 IRQ_TYPE_LEVEL_HIGH>,
				     <GIC_SPI 238 IRQ_TYPE_LEVEL_HIGH>,
				     <GIC_SPI 242 IRQ_TYPE_LEVEL_HIGH>,
				     <GIC_SPI 238 IRQ_TYPE_LEVEL_HIGH>,
				     <GIC_SPI 238 IRQ_TYPE_LEVEL_HIGH>,
				     <GIC_SPI 238 IRQ_TYPE_LEVEL_HIGH>,
				     <GIC_SPI 238 IRQ_TYPE_LEVEL_HIGH>,
				     <GIC_SPI 238 IRQ_TYPE_LEVEL_HIGH>,
				     <GIC_SPI 238 IRQ_TYPE_LEVEL_HIGH>,
				     <GIC_SPI 238 IRQ_TYPE_LEVEL_HIGH>,
				     <GIC_SPI 238 IRQ_TYPE_LEVEL_HIGH>,
				     <GIC_SPI 238 IRQ_TYPE_LEVEL_HIGH>,
				     <GIC_SPI 238 IRQ_TYPE_LEVEL_HIGH>,
				     <GIC_SPI 238 IRQ_TYPE_LEVEL_HIGH>,
				     <GIC_SPI 238 IRQ_TYPE_LEVEL_HIGH>,
				     <GIC_SPI 238 IRQ_TYPE_LEVEL_HIGH>,
				     <GIC_SPI 238 IRQ_TYPE_LEVEL_HIGH>,
				     <GIC_SPI 238 IRQ_TYPE_LEVEL_HIGH>,
				     <GIC_SPI 238 IRQ_TYPE_LEVEL_HIGH>,
				     <GIC_SPI 238 IRQ_TYPE_LEVEL_HIGH>,
				     <GIC_SPI 238 IRQ_TYPE_LEVEL_HIGH>,
				     <GIC_SPI 238 IRQ_TYPE_LEVEL_HIGH>,
				     <GIC_SPI 238 IRQ_TYPE_LEVEL_HIGH>,
				     <GIC_SPI 238 IRQ_TYPE_LEVEL_HIGH>,
				     <GIC_SPI 238 IRQ_TYPE_LEVEL_HIGH>,
				     <GIC_SPI 238 IRQ_TYPE_LEVEL_HIGH>,
				     <GIC_SPI 238 IRQ_TYPE_LEVEL_HIGH>,
				     <GIC_SPI 238 IRQ_TYPE_LEVEL_HIGH>,
				     <GIC_SPI 238 IRQ_TYPE_LEVEL_HIGH>,
				     <GIC_SPI 238 IRQ_TYPE_LEVEL_HIGH>,
				     <GIC_SPI 238 IRQ_TYPE_LEVEL_HIGH>,
				     <GIC_SPI 238 IRQ_TYPE_LEVEL_HIGH>,
				     <GIC_SPI 238 IRQ_TYPE_LEVEL_HIGH>,
				     <GIC_SPI 238 IRQ_TYPE_LEVEL_HIGH>,
				     <GIC_SPI 238 IRQ_TYPE_LEVEL_HIGH>,
				     <GIC_SPI 238 IRQ_TYPE_LEVEL_HIGH>,
				     <GIC_SPI 238 IRQ_TYPE_LEVEL_HIGH>,
				     <GIC_SPI 238 IRQ_TYPE_LEVEL_HIGH>,
				     <GIC_SPI 238 IRQ_TYPE_LEVEL_HIGH>,
				     <GIC_SPI 238 IRQ_TYPE_LEVEL_HIGH>,
				     <GIC_SPI 238 IRQ_TYPE_LEVEL_HIGH>,
				     <GIC_SPI 238 IRQ_TYPE_LEVEL_HIGH>,
				     <GIC_SPI 238 IRQ_TYPE_LEVEL_HIGH>,
				     <GIC_SPI 238 IRQ_TYPE_LEVEL_HIGH>,
				     <GIC_SPI 238 IRQ_TYPE_LEVEL_HIGH>,
				     <GIC_SPI 238 IRQ_TYPE_LEVEL_HIGH>,
				     <GIC_SPI 238 IRQ_TYPE_LEVEL_HIGH>,
				     <GIC_SPI 238 IRQ_TYPE_LEVEL_HIGH>,
				     <GIC_SPI 238 IRQ_TYPE_LEVEL_HIGH>,
				     <GIC_SPI 238 IRQ_TYPE_LEVEL_HIGH>,
				     <GIC_SPI 238 IRQ_TYPE_LEVEL_HIGH>,
				     <GIC_SPI 238 IRQ_TYPE_LEVEL_HIGH>,
				     <GIC_SPI 238 IRQ_TYPE_LEVEL_HIGH>,
				     <GIC_SPI 238 IRQ_TYPE_LEVEL_HIGH>,
				     <GIC_SPI 238 IRQ_TYPE_LEVEL_HIGH>,
				     <GIC_SPI 238 IRQ_TYPE_LEVEL_HIGH>,
				     <GIC_SPI 238 IRQ_TYPE_LEVEL_HIGH>,
				     <GIC_SPI 238 IRQ_TYPE_LEVEL_HIGH>,
				     <GIC_SPI 238 IRQ_TYPE_LEVEL_HIGH>,
				     <GIC_SPI 238 IRQ_TYPE_LEVEL_HIGH>,
				     <GIC_SPI 238 IRQ_TYPE_LEVEL_HIGH>,
				     <GIC_SPI 238 IRQ_TYPE_LEVEL_HIGH>,
				     <GIC_SPI 238 IRQ_TYPE_LEVEL_HIGH>,
				     <GIC_SPI 238 IRQ_TYPE_LEVEL_HIGH>,
				     <GIC_SPI 238 IRQ_TYPE_LEVEL_HIGH>,
				     <GIC_SPI 238 IRQ_TYPE_LEVEL_HIGH>,
				     <GIC_SPI 238 IRQ_TYPE_LEVEL_HIGH>,
				     <GIC_SPI 238 IRQ_TYPE_LEVEL_HIGH>,
				     <GIC_SPI 238 IRQ_TYPE_LEVEL_HIGH>,
				     <GIC_SPI 238 IRQ_TYPE_LEVEL_HIGH>,
				     <GIC_SPI 238 IRQ_TYPE_LEVEL_HIGH>,
				     <GIC_SPI 238 IRQ_TYPE_LEVEL_HIGH>,
				     <GIC_SPI 238 IRQ_TYPE_LEVEL_HIGH>,
				     <GIC_SPI 238 IRQ_TYPE_LEVEL_HIGH>,
				     <GIC_SPI 238 IRQ_TYPE_LEVEL_HIGH>,
				     <GIC_SPI 238 IRQ_TYPE_LEVEL_HIGH>,
				     <GIC_SPI 238 IRQ_TYPE_LEVEL_HIGH>,
				     <GIC_SPI 238 IRQ_TYPE_LEVEL_HIGH>,
				     <GIC_SPI 238 IRQ_TYPE_LEVEL_HIGH>,
				     <GIC_SPI 238 IRQ_TYPE_LEVEL_HIGH>,
				     <GIC_SPI 238 IRQ_TYPE_LEVEL_HIGH>,
				     <GIC_SPI 238 IRQ_TYPE_LEVEL_HIGH>,
				     <GIC_SPI 238 IRQ_TYPE_LEVEL_HIGH>,
				     <GIC_SPI 238 IRQ_TYPE_LEVEL_HIGH>,
				     <GIC_SPI 238 IRQ_TYPE_LEVEL_HIGH>,
				     <GIC_SPI 238 IRQ_TYPE_LEVEL_HIGH>,
				     <GIC_SPI 238 IRQ_TYPE_LEVEL_HIGH>,
				     <GIC_SPI 238 IRQ_TYPE_LEVEL_HIGH>,
				     <GIC_SPI 238 IRQ_TYPE_LEVEL_HIGH>,
				     <GIC_SPI 238 IRQ_TYPE_LEVEL_HIGH>,
				     <GIC_SPI 238 IRQ_TYPE_LEVEL_HIGH>,
				     <GIC_SPI 238 IRQ_TYPE_LEVEL_HIGH>,
				     <GIC_SPI 238 IRQ_TYPE_LEVEL_HIGH>,
				     <GIC_SPI 238 IRQ_TYPE_LEVEL_HIGH>,
				     <GIC_SPI 238 IRQ_TYPE_LEVEL_HIGH>,
				     <GIC_SPI 238 IRQ_TYPE_LEVEL_HIGH>,
				     <GIC_SPI 238 IRQ_TYPE_LEVEL_HIGH>,
				     <GIC_SPI 238 IRQ_TYPE_LEVEL_HIGH>,
				     <GIC_SPI 238 IRQ_TYPE_LEVEL_HIGH>,
				     <GIC_SPI 238 IRQ_TYPE_LEVEL_HIGH>,
				     <GIC_SPI 238 IRQ_TYPE_LEVEL_HIGH>,
				     <GIC_SPI 238 IRQ_TYPE_LEVEL_HIGH>,
				     <GIC_SPI 238 IRQ_TYPE_LEVEL_HIGH>,
				     <GIC_SPI 238 IRQ_TYPE_LEVEL_HIGH>,
				     <GIC_SPI 238 IRQ_TYPE_LEVEL_HIGH>,
				     <GIC_SPI 238 IRQ_TYPE_LEVEL_HIGH>,
				     <GIC_SPI 238 IRQ_TYPE_LEVEL_HIGH>,
				     <GIC_SPI 238 IRQ_TYPE_LEVEL_HIGH>,
				     <GIC_SPI 238 IRQ_TYPE_LEVEL_HIGH>,
				     <GIC_SPI 238 IRQ_TYPE_LEVEL_HIGH>,
				     <GIC_SPI 238 IRQ_TYPE_LEVEL_HIGH>,
				     <GIC_SPI 238 IRQ_TYPE_LEVEL_HIGH>,
				     <GIC_SPI 238 IRQ_TYPE_LEVEL_HIGH>,
				     <GIC_SPI 238 IRQ_TYPE_LEVEL_HIGH>,
				     <GIC_SPI 238 IRQ_TYPE_LEVEL_HIGH>,
				     <GIC_SPI 238 IRQ_TYPE_LEVEL_HIGH>,
				     <GIC_SPI 238 IRQ_TYPE_LEVEL_HIGH>,
				     <GIC_SPI 238 IRQ_TYPE_LEVEL_HIGH>,
				     <GIC_SPI 238 IRQ_TYPE_LEVEL_HIGH>,
				     <GIC_SPI 238 IRQ_TYPE_LEVEL_HIGH>,
				     <GIC_SPI 238 IRQ_TYPE_LEVEL_HIGH>,
				     <GIC_SPI 238 IRQ_TYPE_LEVEL_HIGH>,
				     <GIC_SPI 238 IRQ_TYPE_LEVEL_HIGH>,
				     <GIC_SPI 238 IRQ_TYPE_LEVEL_HIGH>,
				     <GIC_SPI 238 IRQ_TYPE_LEVEL_HIGH>,
				     <GIC_SPI 238 IRQ_TYPE_LEVEL_HIGH>,
				     <GIC_SPI 238 IRQ_TYPE_LEVEL_HIGH>,
				     <GIC_SPI 238 IRQ_TYPE_LEVEL_HIGH>,
				     <GIC_SPI 238 IRQ_TYPE_LEVEL_HIGH>;
			stream-match-mask = <0x7f80>;
			#global-interrupts = <2>;
			#iommu-cells = <1>;

			nvidia,memory-controller = <&mc>;
			status = "okay";
		};



	};

	/*
	 * MGBE VM IRQ configuration
	 * Verbatim from tegra234-base-overlay.dtsi
	 */
	mgbe_vm_irq_config: mgbe-vm-irq-config {
		nvidia,num-vm-irqs = <5>;
		vm_irq1 {
			nvidia,num-vm-channels = <2>;
			nvidia,vm-channels = <0 1>;
			nvidia,vm-num = <0>;
			nvidia,vm-irq-id = <0>;
		};
		vm_irq2 {
			nvidia,num-vm-channels = <2>;
			nvidia,vm-channels = <2 3>;
			nvidia,vm-num = <1>;
			nvidia,vm-irq-id = <1>;
		};
		vm_irq3 {
			nvidia,num-vm-channels = <2>;
			nvidia,vm-channels = <4 5>;
			nvidia,vm-num = <2>;
			nvidia,vm-irq-id = <2>;
		};
		vm_irq4 {
			nvidia,num-vm-channels = <2>;
			nvidia,vm-channels = <6 7>;
			nvidia,vm-num = <3>;
			nvidia,vm-irq-id = <3>;
		};
		vm_irq5 {
			nvidia,num-vm-channels = <2>;
			nvidia,vm-channels = <8 9>;
			nvidia,vm-num = <4>;
			nvidia,vm-irq-id = <4>;
		};
	};

	/* SRAM for BPMP shared memory */
	sram@40000000 {
		compatible = "nvidia,tegra234-sysram", "mmio-sram";
		reg = <0x0 0x40000000 0x0 0x80000>;
		#address-cells = <1>;
		#size-cells = <1>;
		ranges = <0x0 0x0 0x40000000 0x80000>;
		no-memory-wc;

		cpu_bpmp_tx: sram@70000 {
			reg = <0x70000 0x1000>;
			label = "cpu-bpmp-tx";
			pool;
		};

		cpu_bpmp_rx: sram@71000 {
			reg = <0x71000 0x1000>;
			label = "cpu-bpmp-rx";
			pool;
		};
	};

	bpmp: bpmp {
		compatible = "nvidia,tegra234-bpmp", "nvidia,tegra186-bpmp";
		mboxes = <&hsp_top0 TEGRA_HSP_MBOX_TYPE_DB
				    TEGRA_HSP_DB_MASTER_BPMP>;
		shmem = <&cpu_bpmp_tx>, <&cpu_bpmp_rx>;
		#clock-cells = <1>;
		#reset-cells = <1>;
		#power-domain-cells = <1>;
		/* interconnects = <&mc TEGRA234_MEMORY_CLIENT_BPMPR &emc>,
				<&mc TEGRA234_MEMORY_CLIENT_BPMPW &emc>,
				<&mc TEGRA234_MEMORY_CLIENT_BPMPDMAR &emc>,
				<&mc TEGRA234_MEMORY_CLIENT_BPMPDMAW &emc>;
		interconnect-names = "read", "write", "dma-mem", "dma-write";
		iommus = <&smmu_niso1 TEGRA234_SID_BPMP>; */

		bpmp_i2c: i2c {
			compatible = "nvidia,tegra186-bpmp-i2c";
			nvidia,bpmp-bus-id = <5>;
			#address-cells = <1>;
			#size-cells = <0>;
		};

		bpmp_thermal: thermal {
			compatible = "nvidia,tegra186-bpmp-thermal";
			#thermal-sensor-cells = <1>;
		};
	};
};
